# f28p65x_emif1_config_regs register map
Vendor: Texas Instruments
Peripheral module from a debugger description file (folder C2000).
Address unit: 16 bits
Registers are 32-bit, read-write, no defined reset value unless marked. A register's access mark holds for its fields unless they carry their own. Offsets are as the file gives them; lines under a group give offsets from that group; [hi:lo] are bit positions; {n}, {i} and the like mark numbered series; 'fields as' and 'values as' point back to an identical list; <NAME> marks a mode.

## EMIF1_CONFIG_REGS — EMIF1 CONFIG Registers
0x00 EMIF1LOCK — EMIF1 Config Lock Register
  [0] LOCK_EMIF1 — EMIF1 access protection and controller fields lock bit
0x02 EMIF1COMMIT — EMIF1 Config Lock Commit Register
  [0] COMMIT_EMIF1 — EMIF1 access protection and controller select permanent lock
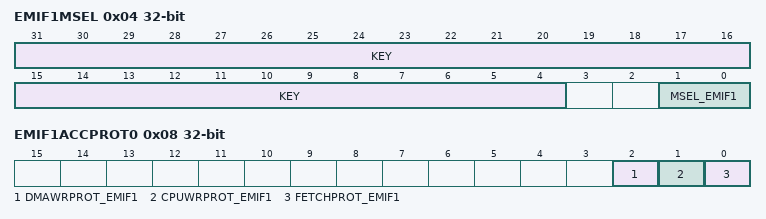
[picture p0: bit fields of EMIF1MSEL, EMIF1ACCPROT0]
0x04 EMIF1MSEL — EMIF1 Controller Sel Register
  [31:4] KEY — KEY to enable the write into MSEL_EMIF1 bits
  [1:0] MSEL_EMIF1 — Controller Select for EMIF1.
0x08 EMIF1ACCPROT0 — EMIF1 Config Register 0
  [2] DMAWRPROT_EMIF1 — DMA WR Protection For EMIF1
  [1] CPUWRPROT_EMIF1 — CPU WR Protection For EMIF1
  [0] FETCHPROT_EMIF1 — Fetch Protection For EMIF1
